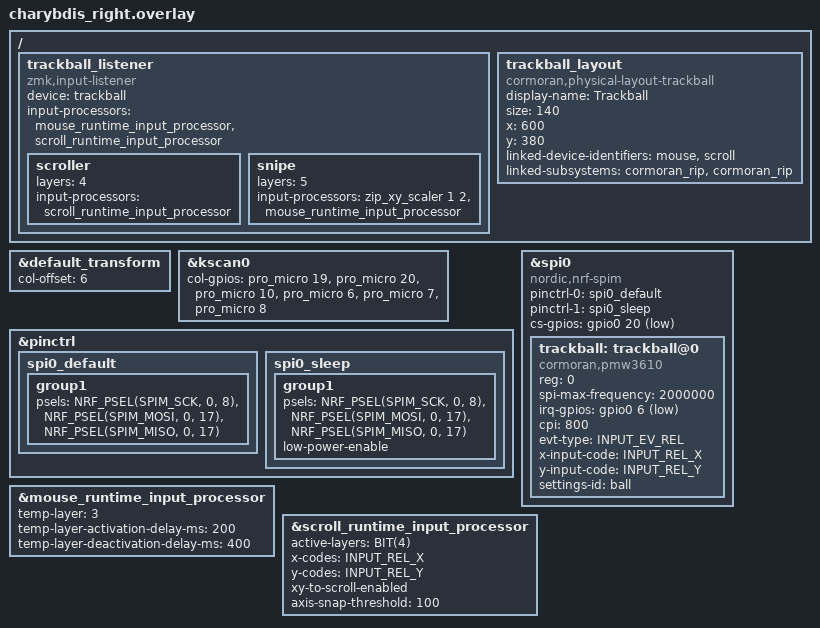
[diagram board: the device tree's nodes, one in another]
/*
 * Copyright (c) 2020 ZMK Contributors
 *
 * SPDX-License-Identifier: MIT
 */

#include "charybdis.dtsi"
#include <dt-bindings/input/input-event-codes.h>

&default_transform {
	col-offset = <6>;
};

&kscan0 {
	col-gpios
		= <&pro_micro 19 (GPIO_ACTIVE_HIGH | GPIO_PULL_DOWN)>
		, <&pro_micro 20 (GPIO_ACTIVE_HIGH | GPIO_PULL_DOWN)>
		, <&pro_micro 10 (GPIO_ACTIVE_HIGH | GPIO_PULL_DOWN)>
		, <&pro_micro 6 (GPIO_ACTIVE_HIGH | GPIO_PULL_DOWN)>
		, <&pro_micro 7 (GPIO_ACTIVE_HIGH | GPIO_PULL_DOWN)>
		, <&pro_micro 8 (GPIO_ACTIVE_HIGH | GPIO_PULL_DOWN)>
		;
};

&pinctrl {
    spi0_default: spi0_default {
        group1 {
            psels = <NRF_PSEL(SPIM_SCK, 0, 8)>,
                <NRF_PSEL(SPIM_MOSI, 0, 17)>,
                <NRF_PSEL(SPIM_MISO, 0, 17)>;
        };
    };

    spi0_sleep: spi0_sleep {
        group1 {
            psels = <NRF_PSEL(SPIM_SCK, 0, 8)>,
                <NRF_PSEL(SPIM_MOSI, 0, 17)>,
                <NRF_PSEL(SPIM_MISO, 0, 17)>;
            low-power-enable;
        };
    };
};

&spi0 {
    status = "okay";
    compatible = "nordic,nrf-spim";
    pinctrl-0 = <&spi0_default>;
    pinctrl-1 = <&spi0_sleep>;
    pinctrl-names = "default", "sleep";
    cs-gpios = <&gpio0 20 GPIO_ACTIVE_LOW>;

    trackball: trackball@0 {
        status = "okay";
        compatible = "cormoran,pmw3610";
        reg = <0>;
        spi-max-frequency = <2000000>;
        irq-gpios = <&gpio0 6 (GPIO_ACTIVE_LOW | GPIO_PULL_UP)>;
        cpi = <800>;
        evt-type = <INPUT_EV_REL>;
        x-input-code = <INPUT_REL_X>;
        y-input-code = <INPUT_REL_Y>;
        settings-id = "ball";
    };
};

/ {
    trackball_listener: trackball_listener {
        compatible = "zmk,input-listener";
        device = <&trackball>;

        input-processors = <&mouse_runtime_input_processor &scroll_runtime_input_processor>;

        scroller {
            layers = <4>;
            input-processors = <&scroll_runtime_input_processor>;
        };

        snipe {
            layers = <5>;
            input-processors = <&zip_xy_scaler 1 2 &mouse_runtime_input_processor>;
        };
    };

    trackball_layout: trackball_layout {
        compatible = "cormoran,physical-layout-trackball";
        display-name = "Trackball";
        size = <140>;
        x = <600>;
        y = <380>;

        linked-device-identifiers = "mouse", "scroll";
        linked-subsystems = "cormoran_rip", "cormoran_rip";
    };
};

// Must come after charybdis.dtsi: runtime-input-processor.dtsi pulls in
// dt-bindings/zmk/keys.h, which redefines RC() and would clash with RC(row, col).
#include <input/processors.dtsi>
#include <input/processors/runtime-input-processor.dtsi>

// Trackball runtime input processors (DYA Studio "Trackball" tab)
&mouse_runtime_input_processor {
    temp-layer = <3>;
    temp-layer-activation-delay-ms = <200>;
    temp-layer-deactivation-delay-ms = <400>;
};

&scroll_runtime_input_processor {
    active-layers = <BIT(4)>;
    x-codes = <INPUT_REL_X>;
    y-codes = <INPUT_REL_Y>;
    xy-to-scroll-enabled;
    axis-snap-threshold = <100>;
};
